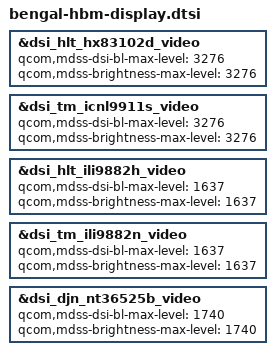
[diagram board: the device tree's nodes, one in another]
/* Copyright (c) 2020, The Linux Foundation. All rights reserved.
 *
 * This program is free software; you can redistribute it and/or modify
 * it under the terms of the GNU General Public License version 2 and
 * only version 2 as published by the Free Software Foundation.
 *
 * This program is distributed in the hope that it will be useful,
 * but WITHOUT ANY WARRANTY; without even the implied warranty of
 * MERCHANTABILITY or FITNESS FOR A PARTICULAR PURPOSE.  See the
 * GNU General Public License for more details.
 */

&dsi_hlt_hx83102d_video {
        qcom,mdss-dsi-bl-max-level = <3276>;
        qcom,mdss-brightness-max-level = <3276>;
};

&dsi_tm_icnl9911s_video {
        qcom,mdss-dsi-bl-max-level = <3276>;
        qcom,mdss-brightness-max-level = <3276>;
};

&dsi_hlt_ili9882h_video {
        qcom,mdss-dsi-bl-max-level = <1637>;
        qcom,mdss-brightness-max-level = <1637>;
};

&dsi_tm_ili9882n_video {
        qcom,mdss-dsi-bl-max-level = <1637>;
        qcom,mdss-brightness-max-level = <1637>;
};

&dsi_djn_nt36525b_video {
        qcom,mdss-dsi-bl-max-level = <1740>;
        qcom,mdss-brightness-max-level = <1740>;
};
